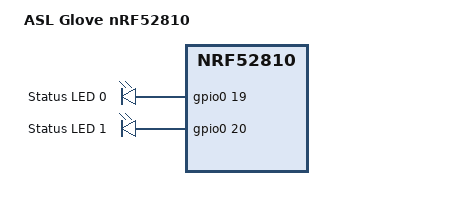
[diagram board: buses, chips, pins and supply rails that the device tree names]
/dts-v1/;
#include <nordic/nrf52810_qfaa.dtsi>
#include <dt-bindings/gpio/gpio.h>

/ {
	model = "ASL Glove nRF52810";
	compatible = "custom,asl-glove-nrf52810";

	aliases {
		led0 = &led0;
		led1 = &led1;
	};

	leds {
		compatible = "gpio-leds";

		led0: led_0 {
			gpios = <&gpio0 19 GPIO_ACTIVE_HIGH>;
			label = "Status LED 0";
		};

		led1: led_1 {
			gpios = <&gpio0 20 GPIO_ACTIVE_HIGH>;
			label = "Status LED 1";
		};
	};
};

&gpiote {
	status = "okay";
};

&gpio0 {
	status = "okay";
};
